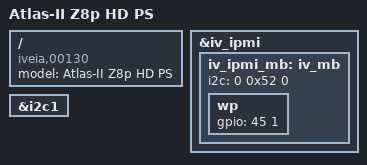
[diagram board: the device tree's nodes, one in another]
#include <atlas-z8-inc.dtsi>

/ {
    model = "Atlas-II Z8p HD PS";
    compatible = "iveia,00130", "iveia,atlas-z8", "xlnx,zynqmp";
};

// Rev B: EEPROM and Temp Sensor moved from I2C1 to I2C0
// Rev C: EEPROM_WP connected to MIO45
// Rev C: Temp Sensor removed (DNS)

&iv_ipmi {
    /delete-node/ iv_mb;

    iv_ipmi_mb: iv_mb {
        i2c = < 0 0x52 0 >;  // <bus_num addr offset>

        wp {
            gpio = < 45 1 >;  // <gpio_num active>
        };
    };
};

&i2c1 {
    /delete-node/ lm75@48;
};

